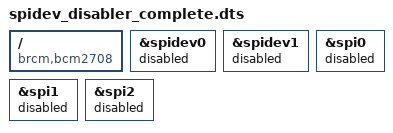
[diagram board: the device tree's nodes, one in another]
/dts-v1/;
/plugin/;

/ {
    compatible = "brcm,bcm2708";

    fragment@0 {
        target = <&spidev0>;
        __overlay__ {
            status = "disabled";
        };
    };

    fragment@1 {
        target = <&spidev1>;
        __overlay__ {
            status = "disabled";
        };
    };

    fragment@2 {
        target = <&spi0>;
        __overlay__ {
            status = "disabled";
        };
    };

    fragment@3 {
        target = <&spi1>;
        __overlay__ {
            status = "disabled";
        };
    };

    fragment@4 {
        target = <&spi2>;
        __overlay__ {
            status = "disabled";
        };
    };
};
